# cslr_timer_001 register map
Vendor: Texas Instruments
Peripheral module from a debugger description file (folder C5535).
Address unit: 16 bits
Registers are 16-bit, read-write, reset 0x0 unless marked. A register's access mark holds for its fields unless they carry their own. Offsets are as the file gives them; lines under a group give offsets from that group; [hi:lo] are bit positions; {n}, {i} and the like mark numbered series; 'fields as' and 'values as' point back to an identical list; <NAME> marks a mode.

## TIM — The TIM controller is used to setup the internal timers. Each timer can be configured as a Watchdog or a General purpose timer.
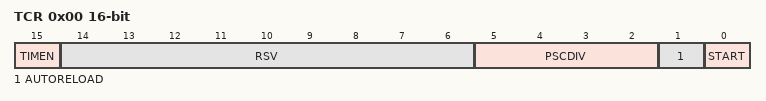
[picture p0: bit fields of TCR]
0x00 TCR access not given — Timer Control
  [15] TIMEN rw — Enables/disables the clocks for the counters to run. This starts both the Prescaler and the main counter.
    0=DISABLE (Timer counters are disabled); 1=ENABLE (Timer coutners are enabled and the prescaler and counter will begin to count down)
  [14:6] RSV — Reserved (access N)
  [5:2] PSCDIV rw — Prescaler divider. The range is 0000 = divide by 2 to 1100 = divide by 8192
  [1] AUTORELOAD rw — automatically reloads the counter when it reaches 0
    0=DISABLE (Auto Reload is disabled); 1=ENABLE (Auto Reload is enabled)
  [0] START rw — When written to this bit loads and starts the counter. If the device is already in the process of counting down and a "1" is written to this bit the counter will be re-loaded with the start value and begin counting down again. When read the bit will be 1 when the counter is counting down this register will read 0 when the counter has stopped.
0x02 TIMPRD1 — Timer period LSW
  [15:0] PRD1 — The Timer period register is 32 bits wide. This is the LSW for the Timer period.
0x03 TIMPRD2 — Timer period MSW
  [15:0] PRD2 — The Timer period register is 32 bits wide. This is the MSW for the Timer period.
0x04 TIMCNT1 — Timer Counter LSW
  [15:0] TIM1 — The timer is 32bits wide. This is the LSW for the timer counter
0x05 TIMCNT2 — Timer Counter MSW
  [15:0] TIM2 — The timer is 32bits wide. This is the MSW for the timer counter
